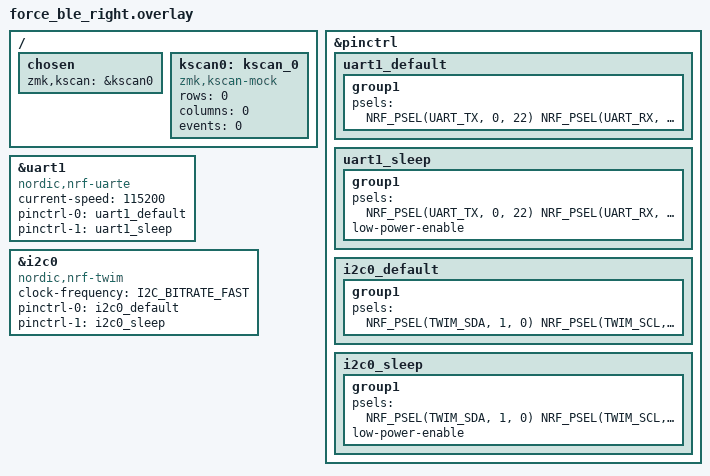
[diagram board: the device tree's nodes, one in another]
#include <dt-bindings/pinctrl/nrf-pinctrl.h>

/ {
    chosen {
        zmk,kscan = &kscan0;
    };

    /*
     * Side-B has no switches. Keep a mock kscan so the peripheral firmware
     * builds cleanly while the right half participates in ZMK split BLE.
     */
    kscan0: kscan_0 {
        compatible = "zmk,kscan-mock";
        rows = <0>;
        columns = <0>;
        events = <0>;
    };
};

&pinctrl {
    uart1_default: uart1_default {
        group1 {
            psels = <
                NRF_PSEL(UART_TX, 0, 22)
                NRF_PSEL(UART_RX, 0, 24)
            >;
        };
    };

    uart1_sleep: uart1_sleep {
        group1 {
            psels = <
                NRF_PSEL(UART_TX, 0, 22)
                NRF_PSEL(UART_RX, 0, 24)
            >;
            low-power-enable;
        };
    };

    i2c0_default: i2c0_default {
        group1 {
            psels = <
                NRF_PSEL(TWIM_SDA, 1, 0)
                NRF_PSEL(TWIM_SCL, 0, 11)
            >;
        };
    };

    i2c0_sleep: i2c0_sleep {
        group1 {
            psels = <
                NRF_PSEL(TWIM_SDA, 1, 0)
                NRF_PSEL(TWIM_SCL, 0, 11)
            >;
            low-power-enable;
        };
    };
};

&uart1 {
    compatible = "nordic,nrf-uarte";
    current-speed = <115200>;
    status = "okay";
    pinctrl-0 = <&uart1_default>;
    pinctrl-1 = <&uart1_sleep>;
    pinctrl-names = "default", "sleep";
};

&i2c0 {
    compatible = "nordic,nrf-twim";
    status = "okay";
    clock-frequency = <I2C_BITRATE_FAST>;
    pinctrl-0 = <&i2c0_default>;
    pinctrl-1 = <&i2c0_sleep>;
    pinctrl-names = "default", "sleep";
};
